# M411_unitB register map
File version: 2.0.2.2
TOSHIBA Cortex-M4 MCU
Registers are 32-bit, read-write, no defined reset value unless marked. A register's access mark holds for its fields unless they carry their own. Offsets are from the block's base; lines under a group give offsets from that group; [hi:lo] are bit positions; {n}, {i} and the like mark numbered series; 'fields as' and 'values as' point back to an identical list; <NAME> marks a mode.

## Memory map
0x40043000 SSP size 0x28 — Synchronous Serial Port (SSP)
0x40049000 UART blocks up to offset 0x4C — UART (Full UART)
0x4004D000 DMA blocks up to offset 0x50 — DMA Controller (DMA)
0x40051000 AD blocks up to offset 0x78 — 12bit A_D Converter (AD)
0x4008F000 T16A2 size 0x14 — 16-bit TimerA (T16A)
0x40090000 T16A3 size 0x14
0x400B8100 INT blocks up to offset 0x5C — Interrupt Controller (INT)
0x400B8200 AES size 0x74 — Advanced Encryption Standard (AES)
0x400B8300 SHA size 0xA0 — Secure Hash Algorithm Processor (SHA)
0x400B8400 ESG size 0x50 — Entropy Seed Generator (ESG)
0x400B9000 MLA blocks up to offset 0x820 — Multiple Length Arithmetic Coprocessor (MLA)
0x400BC100 CPUIF size 0x10 — CPU Interface (CPUIF)
0x400C0700 PH blocks up to offset 0x3C — Port H (PH)
0x400C0800 PJ blocks up to offset 0x3C — Port J (PJ)
0x400C0900 PK blocks up to offset 0x3C — Port K (PK)
0x400C0A00 PL blocks up to offset 0x3C — Port L (PL)
0x400C0B00 PM blocks up to offset 0x3C — Port M (PM)
0x400C0C00 PN blocks up to offset 0x3C — Port N (PN)
0x400C4300 TB3 size 0x30 — 16-bit Timer_Event Counter (TB)
0x400C4400 TB4 size 0x30
0x400E1200 SC2 size 0x34 — SIO_UART (SC)
0x400E1300 SC3 size 0x34
0x400E1400 SC4 size 0x34
0x400E1500 SC5 size 0x34
0x400F2100 WD size 0xC — Watchdog Timer (WD)
0x400F3100 CG size 0x18 — Clock Control (CG)
0x5DFF0000 FC blocks up to offset 0x15C — Flash Control (FC)

## SSP — Synchronous Serial Port (SSP)
Base 0x40043000
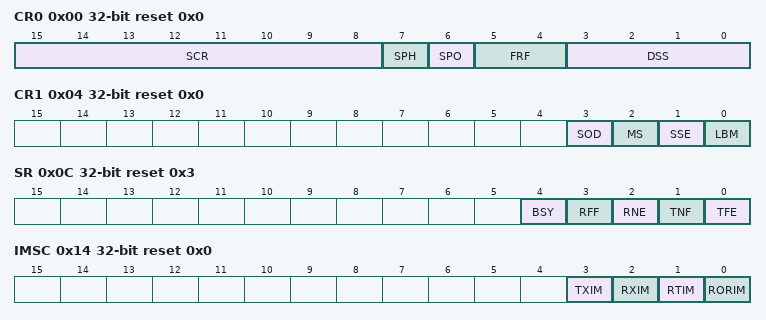
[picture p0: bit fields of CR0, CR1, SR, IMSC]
0x00 CR0 reset 0x0 — SSP Control Register 0
  [15:8] SCR, [7] SPH, [6] SPO, [5:4] FRF, [3:0] DSS
0x04 CR1 reset 0x0 — SSP Control Register 1
  [3] SOD, [2] MS, [1] SSE, [0] LBM
0x08 DR reset 0x0 — SSP Data Register
  [15:0] DATA
0x0C SR ro reset 0x3 — SSP Status Register
  [4] BSY, [3] RFF, [2] RNE, [1] TNF, [0] TFE
0x10 CPSR reset 0x0 — SSP Clock Prescaler Register
  [7:0] CPSDVSR
0x14 IMSC reset 0x0 — SSP Interrupt Mask Set and Clear Register
  [3] TXIM, [2] RXIM, [1] RTIM, [0] RORIM
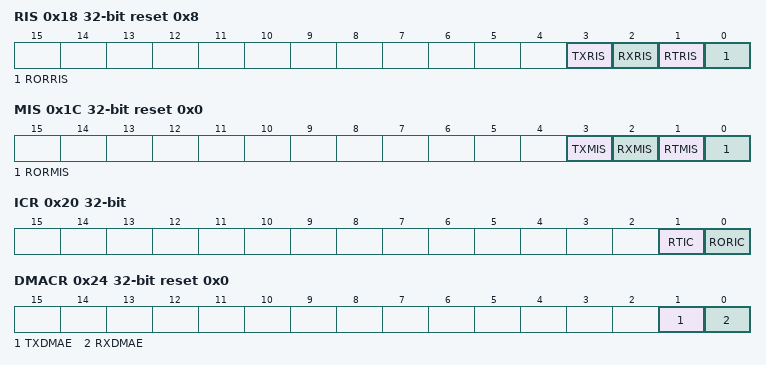
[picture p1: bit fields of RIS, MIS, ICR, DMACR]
0x18 RIS ro reset 0x8 — SSP Raw Interrupt Status Register
  [3] TXRIS, [2] RXRIS, [1] RTRIS, [0] RORRIS
0x1C MIS ro reset 0x0 — SSP Masked Interrupt Status Register
  [3] TXMIS, [2] RXMIS, [1] RTMIS, [0] RORMIS
0x20 ICR wo — SSP Interrupt Clear Register
  [1] RTIC, [0] RORIC
0x24 DMACR reset 0x0 — SSP DMA Control Register
  [1] TXDMAE, [0] RXDMAE

## UART — UART (Full UART)
Base 0x40049000
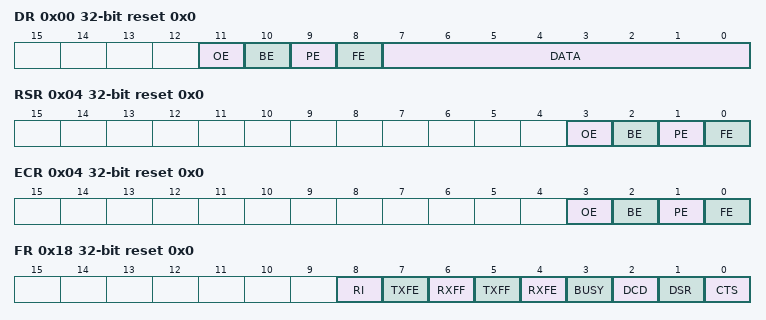
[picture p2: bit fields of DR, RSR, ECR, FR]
0x00 DR reset 0x0 — Data Register
  [11] OE ro, [10] BE ro, [9] PE ro, [8] FE ro, [7:0] DATA
0x04 RSR ro reset 0x0 — Receive Status Register
  [3] OE, [2] BE, [1] PE, [0] FE
0x04 ECR wo reset 0x0 — Error Clear Register
  [3] OE, [2] BE, [1] PE, [0] FE
0x18 FR ro reset 0x0 — Flag Register
  [8] RI, [7] TXFE, [6] RXFF, [5] TXFF, [4] RXFE, [3] BUSY, [2] DCD, [1] DSR, [0] CTS
0x20 ILPR reset 0x0 — IrDA low-power counter Register
  [7:0] ILPDVSR
0x24 IBRD reset 0x0 — Integer Baud Rate Register
  [15:0] BAUDDIVINT
0x28 FBRD reset 0x0 — Fractional Baud Rate Register
  [5:0] BAUDDIVFRAC
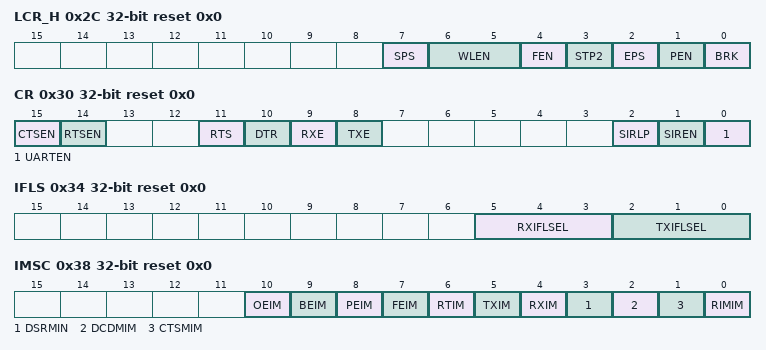
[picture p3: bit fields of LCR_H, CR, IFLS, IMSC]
0x2C LCR_H reset 0x0 — Line Control Register
  [7] SPS, [6:5] WLEN, [4] FEN, [3] STP2, [2] EPS, [1] PEN, [0] BRK
0x30 CR reset 0x0 — Control Register
  [15] CTSEN, [14] RTSEN, [11] RTS, [10] DTR, [9] RXE, [8] TXE, [2] SIRLP, [1] SIREN, [0] UARTEN
0x34 IFLS reset 0x0 — Interrupt FIFO Level Select Register
  [5:3] RXIFLSEL, [2:0] TXIFLSEL
0x38 IMSC reset 0x0 — Interrupt Mask Set_Clear Register
  [10] OEIM, [9] BEIM, [8] PEIM, [7] FEIM, [6] RTIM, [5] TXIM, [4] RXIM, [3] DSRMIN, [2] DCDMIM, [1] CTSMIM, [0] RIMIM
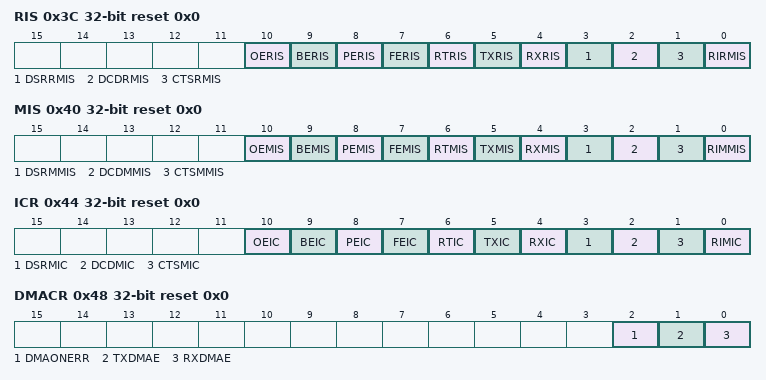
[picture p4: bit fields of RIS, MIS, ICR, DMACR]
0x3C RIS ro reset 0x0 (reset mask 0xFFFFFFF0) — Raw Interrupt Status Register
  [10] OERIS, [9] BERIS, [8] PERIS, [7] FERIS, [6] RTRIS, [5] TXRIS, [4] RXRIS, [3] DSRRMIS, [2] DCDRMIS, [1] CTSRMIS, [0] RIRMIS
0x40 MIS ro reset 0x0 (reset mask 0xFFFFFFF0) — Masked Interrupt Status Register
  [10] OEMIS, [9] BEMIS, [8] PEMIS, [7] FEMIS, [6] RTMIS, [5] TXMIS, [4] RXMIS, [3] DSRMMIS, [2] DCDMMIS, [1] CTSMMIS, [0] RIMMIS
0x44 ICR wo reset 0x0 — Interrupt Clear Register
  [10] OEIC, [9] BEIC, [8] PEIC, [7] FEIC, [6] RTIC, [5] TXIC, [4] RXIC, [3] DSRMIC, [2] DCDMIC, [1] CTSMIC, [0] RIMIC
0x48 DMACR reset 0x0 — DMA Control Register
  [2] DMAONERR, [1] TXDMAE, [0] RXDMAE
